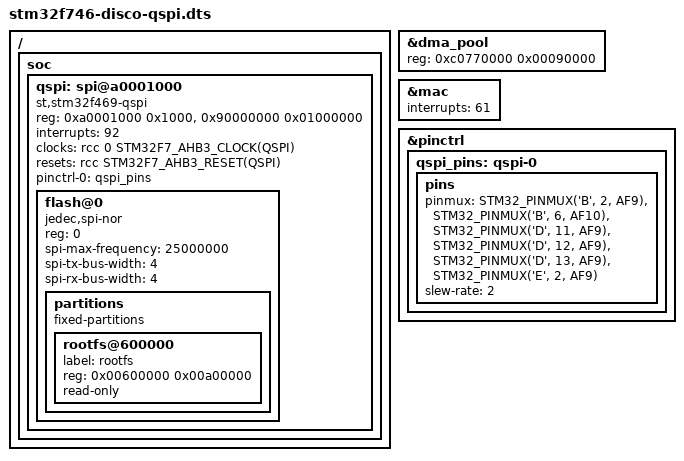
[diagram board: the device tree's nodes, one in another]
// SPDX-License-Identifier: (GPL-2.0+ OR BSD-3-Clause)
/* QSPI-root extension of the native-Linux hammer device tree. */

#include "stm32f746-disco-hammer.dts"

/*
 * DRM fbdev uses two RGB565 scanout buffers from the default coherent pool.
 * Leave another 64 KiB for the reduced stmmac descriptor rings.
 */
&dma_pool {
	reg = <0xc0770000 0x00090000>;
};

/* The STM32F7 NVIC wake line cannot be requested as a shared stmmac IRQ. */
&mac {
	interrupts = <61>;
	interrupt-names = "macirq";
};

/ {
	soc {
		qspi: spi@a0001000 {
			compatible = "st,stm32f469-qspi";
			#address-cells = <1>;
			#size-cells = <0>;
			reg = <0xa0001000 0x1000>, <0x90000000 0x01000000>;
			reg-names = "qspi", "qspi_mm";
			interrupts = <92>;
			clocks = <&rcc 0 STM32F7_AHB3_CLOCK(QSPI)>;
			resets = <&rcc STM32F7_AHB3_RESET(QSPI)>;
			pinctrl-0 = <&qspi_pins>;
			pinctrl-names = "default";
			status = "okay";

			flash@0 {
				compatible = "jedec,spi-nor";
				reg = <0>;
				/*
				 * The nominal 108 MHz setting selects an effective 100 MHz
				 * QSPI clock and intermittently BusFaults during Linux
				 * memory-mapped reads on this board. Use a 50 MHz ceiling for
				 * a conservative root-filesystem transport. Intermittent
				 * SquashFS-superblock corruption remained at 50 MHz with
				 * indirect FIFO reads, so use 25 MHz for boot reliability.
				 */
				spi-max-frequency = <25000000>;
				spi-tx-bus-width = <4>;
				spi-rx-bus-width = <4>;

				partitions {
					compatible = "fixed-partitions";
					#address-cells = <1>;
					#size-cells = <1>;

					rootfs@600000 {
						label = "rootfs";
						reg = <0x00600000 0x00a00000>;
						read-only;
					};
				};
			};
		};
	};
};

&pinctrl {
	qspi_pins: qspi-0 {
		pins {
			pinmux = <STM32_PINMUX('B', 2, AF9)>,  /* CLK */
				 <STM32_PINMUX('B', 6, AF10)>, /* BK1_NCS */
				 <STM32_PINMUX('D', 11, AF9)>, /* BK1_IO0 */
				 <STM32_PINMUX('D', 12, AF9)>, /* BK1_IO1 */
				 <STM32_PINMUX('D', 13, AF9)>, /* BK1_IO3 */
				 <STM32_PINMUX('E', 2, AF9)>;  /* BK1_IO2 */
			slew-rate = <2>;
		};
	};
};
